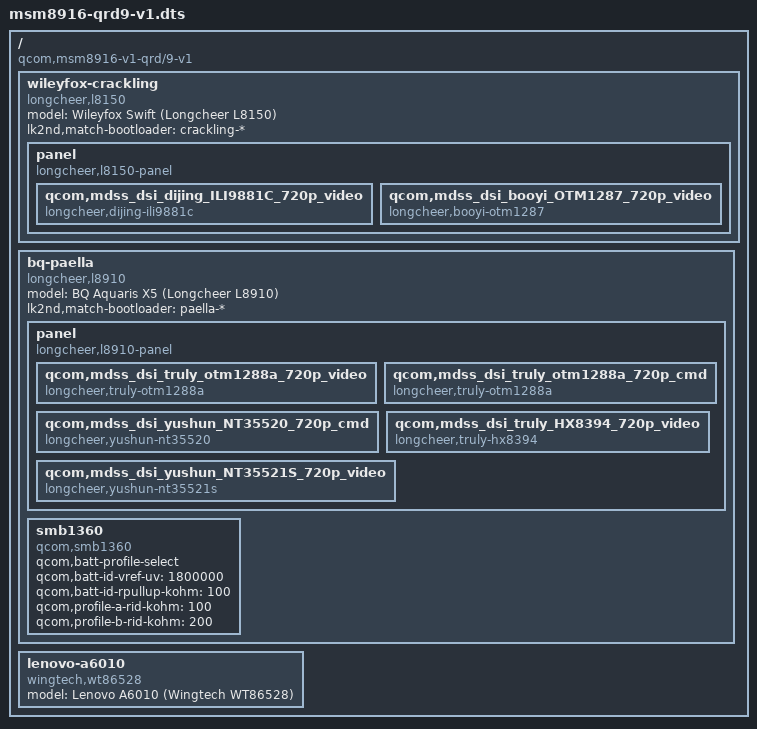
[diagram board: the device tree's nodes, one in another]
// SPDX-License-Identifier: GPL-2.0-only

/dts-v1/;

/include/ "skeleton.dtsi"

/ {
	compatible = "qcom,msm8916-v1-qrd/9-v1", "qcom,msm8916";

	wileyfox-crackling {
		model = "Wileyfox Swift (Longcheer L8150)";
		compatible = "longcheer,l8150", "qcom,msm8916", "lk2nd,device";
		lk2nd,match-bootloader = "crackling-*";

		panel {
			compatible = "longcheer,l8150-panel";

			/* TODO: qcom,mdss_dsi_truly_otm1288a_720p_video */
			qcom,mdss_dsi_dijing_ILI9881C_720p_video {
				compatible = "longcheer,dijing-ili9881c";
			};
			qcom,mdss_dsi_booyi_OTM1287_720p_video {
				compatible = "longcheer,booyi-otm1287";
			};
		};
	};

	bq-paella {
		model = "BQ Aquaris X5 (Longcheer L8910)";
		compatible = "longcheer,l8910", "qcom,msm8916", "lk2nd,device";
		lk2nd,match-bootloader = "paella-*";

		panel {
			compatible = "longcheer,l8910-panel";

			qcom,mdss_dsi_truly_otm1288a_720p_video {
				compatible = "longcheer,truly-otm1288a";
			};
			qcom,mdss_dsi_truly_otm1288a_720p_cmd {
				compatible = "longcheer,truly-otm1288a";
			};
			qcom,mdss_dsi_yushun_NT35520_720p_cmd {
				compatible = "longcheer,yushun-nt35520";
			};
			qcom,mdss_dsi_truly_HX8394_720p_video {
				compatible = "longcheer,truly-hx8394";
			};
			qcom,mdss_dsi_yushun_NT35521S_720p_video {
				compatible = "longcheer,yushun-nt35521s";
			};
		};

		smb1360 {
			compatible = "qcom,smb1360";

			qcom,batt-profile-select;
			qcom,batt-id-vref-uv = <1800000>;
			qcom,batt-id-rpullup-kohm = <100>;
			qcom,profile-a-rid-kohm = <100>;
			qcom,profile-b-rid-kohm = <200>;
		};
	};

	lenovo-a6010 {
		model = "Lenovo A6010 (Wingtech WT86528)";
		compatible = "wingtech,wt86528", "qcom,msm8916", "lk2nd,device";
		/include/ "msm8916-wingtech-wt865x8.dtsi"
	};
};
